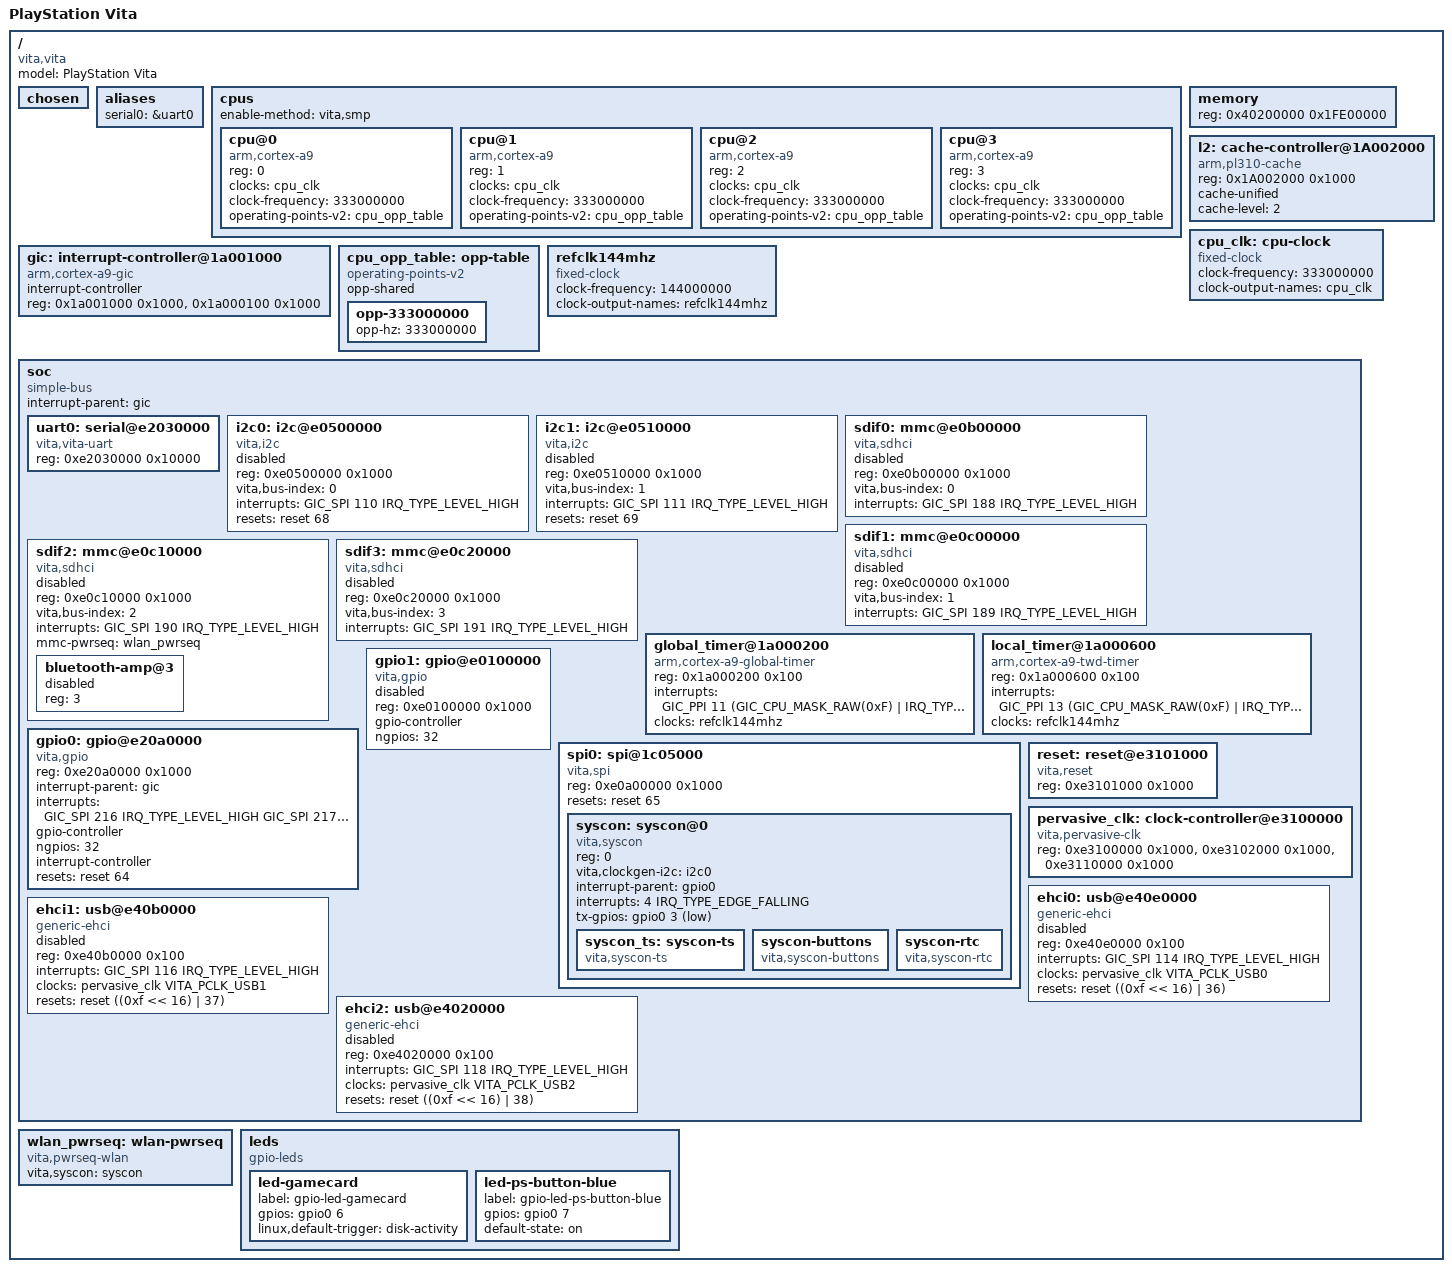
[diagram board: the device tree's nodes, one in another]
// SPDX-License-Identifier: GPL-2.0
/*
 * Base Device Tree Source for the PlayStation Vita
 */

/dts-v1/;

/ {
	model = "PlayStation Vita";
	compatible = "vita,vita";

	#address-cells = <1>;
	#size-cells = <1>;

	chosen {
		#address-cells = <1>;
		#size-cells = <1>;
		ranges;
	};

	aliases {
		serial0 = &uart0;
	};

	cpus {
		#address-cells = <1>;
		#size-cells = <0>;
		enable-method = "vita,smp";

		cpu@0 {
			device_type = "cpu";
			compatible = "arm,cortex-a9";
			reg = <0>;
			clocks = <&cpu_clk>;
			clock-frequency = <333000000>;
			operating-points-v2 = <&cpu_opp_table>;
		};

		cpu@1 {
			device_type = "cpu";
			compatible = "arm,cortex-a9";
			reg = <1>;
			clocks = <&cpu_clk>;
			clock-frequency = <333000000>;
			operating-points-v2 = <&cpu_opp_table>;
		};

		cpu@2 {
			device_type = "cpu";
			compatible = "arm,cortex-a9";
			reg = <2>;
			clocks = <&cpu_clk>;
			clock-frequency = <333000000>;
			operating-points-v2 = <&cpu_opp_table>;
		};

		cpu@3 {
			device_type = "cpu";
			compatible = "arm,cortex-a9";
			reg = <3>;
			clocks = <&cpu_clk>;
			clock-frequency = <333000000>;
			operating-points-v2 = <&cpu_opp_table>;
		};
	};

	memory {
		device_type = "memory";
		reg = <0x40200000 0x1FE00000>;
	};

	l2: cache-controller@1A002000 {
		compatible = "arm,pl310-cache";
		reg = <0x1A002000 0x1000>;
		cache-unified;
		cache-level = <2>;
	};

	gic: interrupt-controller@1a001000 {
		compatible = "arm,cortex-a9-gic";
		#interrupt-cells = <3>;
		#address-cells = <0>;
		interrupt-controller;
		reg = <0x1a001000 0x1000>,
		      <0x1a000100 0x1000>;
	};

	cpu_clk: cpu-clock {
		compatible = "fixed-clock";
		#clock-cells = <0>;
		clock-frequency = <333000000>;
		clock-output-names = "cpu_clk";
	};

	cpu_opp_table: opp-table {
		compatible = "operating-points-v2";
		opp-shared;

		opp-333000000 {
			opp-hz = /bits/ 64 <333000000>;
		};
	};

	refclk144mhz: refclk144mhz {
		compatible = "fixed-clock";
		#clock-cells = <0>;
		clock-frequency = <144000000>;
		clock-output-names = "refclk144mhz";
	};

	soc {
		#address-cells = <1>;
		#size-cells = <1>;
		compatible = "simple-bus";
		interrupt-parent = <&gic>;
		ranges;

		uart0: serial@e2030000 {
			compatible = "vita,vita-uart";
			reg = <0xe2030000 0x10000>;
		};

		/*
		 * I2C controllers.
		 * VitaOS interrupt codes 0x8E-0x8F (from SceKernelIntrMgr wiki).
		 * GIC_SPI = code - 32: I2C0=110, I2C1=111.
		 */
		i2c0: i2c@e0500000 {
			compatible = "vita,i2c";
			reg = <0xe0500000 0x1000>;
			vita,bus-index = <0>;
			interrupts = <GIC_SPI 110 IRQ_TYPE_LEVEL_HIGH>;
			resets = <&reset 68>;
			#address-cells = <1>;
			#size-cells = <0>;
			status = "disabled";
		};

		i2c1: i2c@e0510000 {
			compatible = "vita,i2c";
			reg = <0xe0510000 0x1000>;
			vita,bus-index = <1>;
			interrupts = <GIC_SPI 111 IRQ_TYPE_LEVEL_HIGH>;
			resets = <&reset 69>;
			#address-cells = <1>;
			#size-cells = <0>;
			status = "disabled";
		};

		/*
		 * SDIF controllers — standard SDHCI.
		 * VitaOS interrupt codes: 0xDC-0xDF (from psvcmd56 RE).
		 * Mapping: VitaOS code = GIC hardware IRQ ID,
		 * GIC_SPI N = hardware IRQ N+32, so SPI = code - 32.
		 *   SDIF0: 0xDC = 220 → GIC_SPI 188
		 *   SDIF1: 0xDD = 221 → GIC_SPI 189
		 *   SDIF2: 0xDE = 222 → GIC_SPI 190
		 *   SDIF3: 0xDF = 223 → GIC_SPI 191
		 */
		sdif0: mmc@e0b00000 {
			compatible = "vita,sdhci";
			reg = <0xe0b00000 0x1000>;
			vita,bus-index = <0>;
			interrupts = <GIC_SPI 188 IRQ_TYPE_LEVEL_HIGH>;
			status = "disabled";
		};

		sdif1: mmc@e0c00000 {
			compatible = "vita,sdhci";
			reg = <0xe0c00000 0x1000>;
			vita,bus-index = <1>;
			interrupts = <GIC_SPI 189 IRQ_TYPE_LEVEL_HIGH>;
			status = "disabled";
		};

		sdif2: mmc@e0c10000 {
			compatible = "vita,sdhci";
			reg = <0xe0c10000 0x1000>;
			#address-cells = <1>;
			#size-cells = <0>;
			vita,bus-index = <2>;
			interrupts = <GIC_SPI 190 IRQ_TYPE_LEVEL_HIGH>;
			mmc-pwrseq = <&wlan_pwrseq>;
			status = "disabled";

			/* The Vita does not use the SD8787 Bluetooth AMP function. */
			bluetooth-amp@3 {
				reg = <3>;
				status = "disabled";
			};
		};

		sdif3: mmc@e0c20000 {
			compatible = "vita,sdhci";
			reg = <0xe0c20000 0x1000>;
			vita,bus-index = <3>;
			interrupts = <GIC_SPI 191 IRQ_TYPE_LEVEL_HIGH>;
			status = "disabled";
		};

		global_timer@1a000200 {
			compatible = "arm,cortex-a9-global-timer";
			reg = <0x1a000200 0x100>;
			interrupts = <GIC_PPI 11 (GIC_CPU_MASK_RAW(0xF) | IRQ_TYPE_EDGE_RISING)>;
			clocks = <&refclk144mhz>;
		};

		local_timer@1a000600 {
			compatible = "arm,cortex-a9-twd-timer";
			reg = <0x1a000600 0x100>;
			interrupts = <GIC_PPI 13 (GIC_CPU_MASK_RAW(0xF) | IRQ_TYPE_EDGE_RISING)>;
			clocks = <&refclk144mhz>;
		};

		gpio0: gpio@e20a0000 {
			compatible = "vita,gpio";
			#address-cells = <1>;
			#size-cells = <1>;
			reg = <0xe20a0000 0x1000>;

			interrupt-parent = <&gic>;
			interrupts = <GIC_SPI 216 IRQ_TYPE_LEVEL_HIGH
				      GIC_SPI 217 IRQ_TYPE_LEVEL_HIGH
				      GIC_SPI 218 IRQ_TYPE_LEVEL_HIGH
				      GIC_SPI 219 IRQ_TYPE_LEVEL_HIGH
				      GIC_SPI 220 IRQ_TYPE_LEVEL_HIGH>;

			gpio-controller;
			#gpio-cells = <2>;
			ngpios = <32>;

			interrupt-controller;
			#interrupt-cells = <2>;

			resets = <&reset 64>;
			reset-names = "gpio0_reset";
		};

		/* Second GPIO bank.  Only pin 3 has a known consumer: on the
		 * PSTV (Dolce) it is the external Type-A port's VBUS enable,
		 * driven by VitaOS as ksceGpioSetPortMode(1, 3, 0) followed by
		 * ksceGpioPortSet(1, 3).  Setting the pin without first
		 * switching its direction to output silently does nothing.
		 *
		 * The bank is described output-only: its reset index and
		 * interrupt routing have never been identified, so neither is
		 * claimed.  Enabled per board.
		 */
		gpio1: gpio@e0100000 {
			compatible = "vita,gpio";
			reg = <0xe0100000 0x1000>;

			gpio-controller;
			#gpio-cells = <2>;
			ngpios = <32>;

			status = "disabled";
		};

		spi0: spi@1c05000 {
			compatible = "vita,spi";
			reg = <0xe0a00000 0x1000>;
			#address-cells = <1>;
			#size-cells = <0>;

			resets = <&reset 65>;
			reset-names = "spi0_reset";

			syscon: syscon@0 {
				compatible = "vita,syscon";
				reg = <0>;
				#address-cells = <0>;
				#size-cells = <0>;

				vita,clockgen-i2c = <&i2c0>;

				interrupt-parent = <&gpio0>;
				interrupts = <4 IRQ_TYPE_EDGE_FALLING>;

				tx-gpios = <&gpio0 3 GPIO_ACTIVE_LOW>;

				syscon_ts: syscon-ts {
					compatible = "vita,syscon-ts";
				};

				syscon-buttons {
					compatible = "vita,syscon-buttons";
				};

				syscon-rtc {
					compatible = "vita,syscon-rtc";
				};
			};

		};

		reset: reset@e3101000 {
			compatible = "vita,reset";
			#reset-cells = <1>;
			reg = <0xe3101000 0x1000>;
		};

		/* Pervasive clock gates.  Mirrors the reset block's register
		 * layout (one 32-bit register per device, index = offset/4),
		 * but a set bit enables the device's clock. */
		pervasive_clk: clock-controller@e3100000 {
			compatible = "vita,pervasive-clk";
			#clock-cells = <1>;
			/* Optional vita,usb-hostmode-mask selects buses for the
			 * Sony host-mode park-window sequence.  Its safe default is
			 * bus 2 only; boards must opt in explicitly.
			 * Optional vita,clock-gate-indices lists non-USB clock IDs
			 * physically available on that board.  With no list, only
			 * the ABI-stable USB gates are registered.
			 */
			/* Reg 0: pervasive flags page (+0x084..0x8C USB mode
			 * flags).  Reg 1: clk gate page (+0x090..0x98 USB
			 * buses).  Reg 2: USB PHY page (ready bit +0xF30,
			 * bus-2 location; buses 0/1 PHY pages unmapped).
			 * The reset page (0xE3101000) is intentionally not
			 * listed: reset-vita owns that region; this driver
			 * reaches it with an unclaimed ioremap for the
			 * host-mode park sequence only. */
			reg = <0xe3100000 0x1000>,
			      <0xe3102000 0x1000>,
			      <0xe3110000 0x1000>;
		};

		/* USB 2.0 host controllers: three EHCI 1.0 cores, one per
		 * bus (SceUsbd names them SceUsbEhci0/1/2), each with a
		 * one-port OHCI 1.0 companion at +0x200 in the same page.
		 * Identification and IRQs from the 2026-08-18 EHCI/OHCI
		 * campaign (lab/usb-ehci-ohci-writeup-2026-08-18.md in the
		 * research repo): every live register value matches the
		 * EHCI 1.0 spec, and SceUsbd registers ISRs at VitaOS
		 * codes 146/148/150 -> GIC_SPI 114/116/118 (code - 32).
		 *
		 * The OHCI companions are deliberately NOT described: their
		 * register window (+0x200) only decodes under firmware-side
		 * conditions Linux has not reproduced, and probing it
		 * external-aborts and poisons the whole bus page until the
		 * next power cycle (one-way).  Do not add ohci-platform
		 * nodes for these buses until that decode gate is
		 * understood.
		 *
		 * Pervasive wiring per bus: gate 0xE3102090/94/98 (clock
		 * ids 0/1/2, mask 0xF) and reset index 36/37/38 (mask 0xF).
		 * The EHCI window itself decodes only A0-A7 (0x100 bytes;
		 * it mirrors at every 0x100 stride above that).
		 *
		 * Vendor block at +0x94/+0x98/+0xA4 (SceUsbd writes
		 * +0x94 = 0x01000010 at init): ehci-platform does not touch
		 * these; add a vita shim if the cores misbehave without it.
		 */
		ehci0: usb@e40e0000 {
			compatible = "generic-ehci";
			reg = <0xe40e0000 0x100>;
			interrupts = <GIC_SPI 114 IRQ_TYPE_LEVEL_HIGH>;
			clocks = <&pervasive_clk VITA_PCLK_USB0>;
			resets = <&reset ((0xf << 16) | 36)>;
			status = "disabled";
		};

		ehci1: usb@e40b0000 {
			compatible = "generic-ehci";
			reg = <0xe40b0000 0x100>;
			interrupts = <GIC_SPI 116 IRQ_TYPE_LEVEL_HIGH>;
			clocks = <&pervasive_clk VITA_PCLK_USB1>;
			resets = <&reset ((0xf << 16) | 37)>;
			status = "disabled";
		};

		ehci2: usb@e4020000 {
			compatible = "generic-ehci";
			reg = <0xe4020000 0x100>;
			interrupts = <GIC_SPI 118 IRQ_TYPE_LEVEL_HIGH>;
			clocks = <&pervasive_clk VITA_PCLK_USB2>;
			resets = <&reset ((0xf << 16) | 38)>;
			status = "disabled";
		};
	};

	wlan_pwrseq: wlan-pwrseq {
		compatible = "vita,pwrseq-wlan";
		vita,syscon = <&syscon>;
	};

	leds {
		compatible = "gpio-leds";

		led-gamecard {
			label = "gpio-led-gamecard";
			gpios = <&gpio0 6 GPIO_ACTIVE_HIGH>;
			linux,default-trigger = "disk-activity";
		};

		led-ps-button-blue {
			label = "gpio-led-ps-button-blue";
			gpios = <&gpio0 7 GPIO_ACTIVE_HIGH>;
			default-state = "on";
		};
	};
};
